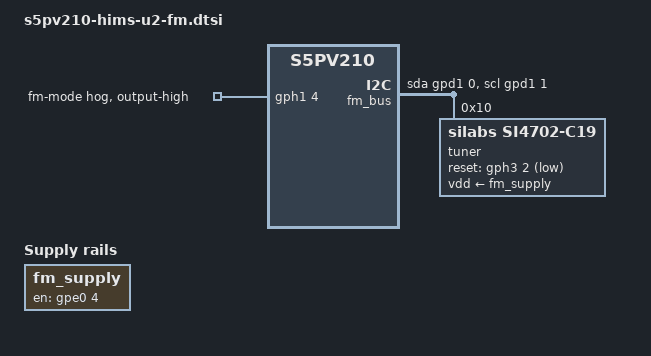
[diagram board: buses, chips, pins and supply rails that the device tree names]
// SPDX-License-Identifier: GPL-2.0-only
/ {
	aliases {
		i2c10 = &fm_bus;
	};

	fm_supply: regulator-fm {
		compatible = "regulator-fixed";
		regulator-name = "fm-vdd";
		gpio = <&gpe0 4 GPIO_ACTIVE_HIGH>;
		enable-active-high;
	};

	fm_bus: i2c-fm {
		compatible = "i2c-gpio";
		sda-gpios = <&gpd1 0 (GPIO_ACTIVE_HIGH | GPIO_OPEN_DRAIN)>;
		scl-gpios = <&gpd1 1 (GPIO_ACTIVE_HIGH | GPIO_OPEN_DRAIN)>;
		i2c-gpio,delay-us = <10>;
		i2c-gpio,timeout-ms = <100>;
		#address-cells = <1>;
		#size-cells = <0>;

		tuner@10 {
			compatible = "silabs,si4702-c19";
			reg = <0x10>;
			vdd-supply = <&fm_supply>;
			reset-gpios = <&gph3 2 GPIO_ACTIVE_LOW>;
			silabs,channel-spacing-khz = <100>;
			silabs,deemphasis-us = <50>;
			silabs,use-crystal;
		};
	};
};

&gph1 {
	/* Board control held high by the factory; not a Si4702 protocol signal. */
	fm-mode-hog {
		gpio-hog;
		gpios = <4 GPIO_ACTIVE_HIGH>;
		output-high;
		line-name = "fm-mode";
	};
};
